AUTOSAR XML (schema 314)
package /ComponentType
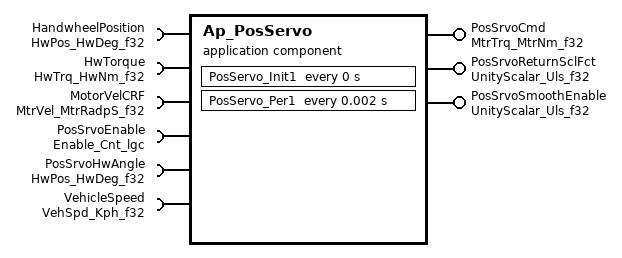
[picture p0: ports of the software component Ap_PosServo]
  application software component type Ap_PosServo
    provide port PosSrvoCmd: unqueued-sender-com-spec{data-element=MtrNm_f32, can-invalidate=false, init-value=D_ZERO_ULS_F32}, provided-interface=MtrTrq_MtrNm_f32
    provide port PosSrvoReturnSclFct: unqueued-sender-com-spec{data-element=Uls_f32, can-invalidate=false, init-value=D_ONE_ULS_F32}, provided-interface=UnityScalar_Uls_f32
    provide port PosSrvoSmoothEnable: unqueued-sender-com-spec{data-element=Uls_f32, can-invalidate=false, init-value=D_ZERO_ULS_F32}, provided-interface=UnityScalar_Uls_f32
    6 x require port:
      HandwheelPosition: unqueued-receiver-com-spec{data-element=HwDeg_f32, init-value=D_ZERO_ULS_F32}, required-interface=HwPos_HwDeg_f32
      HwTorque: unqueued-receiver-com-spec{data-element=HwNm_f32, init-value=D_ZERO_ULS_F32}, required-interface=HwTrq_HwNm_f32
      MotorVelCRF: unqueued-receiver-com-spec{data-element=MtrRadpS_f32, init-value=D_ZERO_ULS_F32}, required-interface=MtrVel_MtrRadpS_f32
      PosSrvoEnable: unqueued-receiver-com-spec{data-element=Cnt_lgc, init-value=D_FALSE_CNT_LGC}, required-interface=Enable_Cnt_lgc
      PosSrvoHwAngle: unqueued-receiver-com-spec{data-element=HwDeg_f32, init-value=D_ZERO_ULS_F32}, required-interface=HwPos_HwDeg_f32
      VehicleSpeed: unqueued-receiver-com-spec{data-element=Kph_f32, init-value=D_ZERO_ULS_F32}, required-interface=VehSpd_Kph_f32
  internal behavior Ap_PosServo_InternalBehavior: component=Ap_PosServo
    timing event PosServo_Init1_InitEvent: start-on-event=PosServo_Init1, period=0
    timing event TMT_PosServo_Per1: start-on-event=PosServo_Per1, period=0.002
    port-api-options:
      enable-take-address=false, indirect-api=false, port=HandwheelPosition
      enable-take-address=false, indirect-api=false, port=HwTorque
      enable-take-address=false, indirect-api=false, port=MotorVelCRF
      enable-take-address=false, indirect-api=false, port=PosSrvoCmd
      enable-take-address=false, indirect-api=false, port=PosSrvoEnable
      enable-take-address=false, indirect-api=false, port=PosSrvoHwAngle
      enable-take-address=false, indirect-api=false, port=PosSrvoReturnSclFct
      enable-take-address=false, indirect-api=false, port=PosSrvoSmoothEnable
      enable-take-address=false, indirect-api=false, port=VehicleSpeed
    runnable PosServo_Init1
    runnable PosServo_Per1
      6 x data read access:
        READ_HandwheelPosition_HwDeg_f32: data-element=HandwheelPosition.HwDeg_f32
        READ_HwTorque_HwNm_f32: data-element=HwTorque.HwNm_f32
        READ_MotorVelCRF_MtrRadpS_f32: data-element=MotorVelCRF.MtrRadpS_f32
        READ_PosSrvoEnable_Cnt_lgc: data-element=PosSrvoEnable.Cnt_lgc
        READ_PosSrvoHwAngle_HwDeg_f32: data-element=PosSrvoHwAngle.HwDeg_f32
        READ_VehicleSpeed_Kph_f32: data-element=VehicleSpeed.Kph_f32
      data write access WRITE_PosSrvoCmd_MtrNm_f32: data-element=PosSrvoCmd.MtrNm_f32
      data write access WRITE_PosSrvoReturnSclFct_Uls_f32: data-element=PosSrvoReturnSclFct.Uls_f32
      data write access WRITE_PosSrvoSmoothEnable_Uls_f32: data-element=PosSrvoSmoothEnable.Uls_f32
  swc implementation Ap_PosServo_Implementation: behavior=Ap_PosServo_InternalBehavior
    code-descriptors:
      code Code: type=SRC
